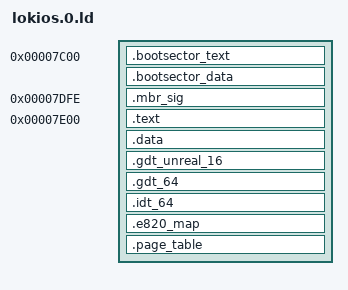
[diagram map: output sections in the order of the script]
SECTIONS
{
    /* PXE loads us into memory at 0x7c00, so link ourselves at that base
     * address. */
    . = 0x7c00;
    .bootsector_text :
    {
        lokios.0/bootsector/entry.o(.text)
        lokios.0/bootsector/*(.text)
    }
    .bootsector_data :
    {
        lokios.0/bootsector/*(.data)
    }
    ASSERT(. <= 0x7DB4, "boot sector crashed into disk ID")

    /* Include a valid MBR signature for booting off disk. */
    . = 0x7dfe;
    .mbr_sig :
    {
        BYTE(0x55)
        BYTE(0xAA)
    }

    /* That's the end of the boot sector.  If we PXE-booted the rest of the
     * code is already in memory.  If we MBR-booted then the bootsector has
     * gone and loaded the rest of the code into memory.  In either case, they
     * will then branch into code at or above 0x7E00. */
    . = 0x7e00;
    .text :
    {
        *(.text)
    }
    .data :
    {
        *(.data)
    } = 0xCC

    /* Provide a global descriptor table to use for the swtich to 16-bit
     * unreal mode. */
    . = ALIGN(64);
    .gdt_unreal_16 :
    {
        _gdt_unreal_16 = .;
        QUAD(0x0000000000000000);
        QUAD(0x00CF92000000FFFF);

        _gdt_unreal_16_desc = .;
        SHORT(_gdt_unreal_16_desc - _gdt_unreal_16 - 1);
        LONG(_gdt_unreal_16);
    }

    /* Provide a global descriptor table to use for the switch to 64-bit
     * mode. */
    . = ALIGN(64);
    .gdt_64 :
    {
        _gdt_64 = .;
        QUAD(0x0000000000000000);
        QUAD(0x00209A0000000000);   /* Code descriptor */
        QUAD(0x0000920000000000);   /* Data descriptor */

        _gdt_64_desc = .;
        SHORT(_gdt_64_desc - _gdt_64 - 1);
        LONG(_gdt_64);
    }

    /* Provide an empty interrupt descriptor table.  TODO: Figure out what to
     * really put here. */
    . = ALIGN(64);
    .idt_64 :
    {
        _idt_64 = .;
        BYTE(0);
        _idt_64_desc = .;
        SHORT(_idt_64_desc - _idt_64 - 1);
        LONG(_idt_64);
    }

    /* Provide at least 4096 bytes to hold the E820 map.  This should be more
     * than enough (I hope).  Before we've loaded the E820 map, this region of
     * memory can also be used for a disk IO bounce buffer. */
    .e820_map :
    {
        _pre_e820_bounce_buffer = .;
        _e820_end = .;
        SHORT(0xFFFF);
        _e820_map = .;
        . += 4096;
        . = ALIGN(4096);
    } = 0xDD
    _e820_last_max_entry = . - 24;

    /* Provide a page table that identity-maps the first 4M of memory via a
     * huge page. */
    .page_table :
    {
        _page_table = .;
        ASSERT(_page_table == ALIGN(4096), "page table misaligned");
        QUAD((_page_table + 0x00001000) | 3);
        . = ALIGN(4096);
        QUAD((_page_table + 0x00002000) | 3);
        . = ALIGN(4096);
        QUAD((_page_table + 0x00003000) | 3);
        QUAD(0x0000000000200083);
        . = ALIGN(4096);
        QUAD(0x0000000000000081);
        QUAD(0x0000000000001081);
        QUAD(0x0000000000002081);
        QUAD(0x0000000000003081);
        QUAD(0x0000000000004081);
        QUAD(0x0000000000005081);
        QUAD(0x0000000000006081);
        QUAD(0x0000000000007081);
        QUAD(0x0000000000008081);
        QUAD(0x0000000000009081);
        QUAD(0x000000000000A081);
        QUAD(0x000000000000B081);
        QUAD(0x000000000000C081);
        QUAD(0x000000000000D081);
        QUAD(0x000000000000E081);
        QUAD(0x000000000000F081);
        QUAD(0x0000000000010081);
        QUAD(0x0000000000011081);
        QUAD(0x0000000000012081);
        QUAD(0x0000000000013081);
        QUAD(0x0000000000014081);
        QUAD(0x0000000000015081);
        QUAD(0x0000000000016081);
        QUAD(0x0000000000017081);
        QUAD(0x0000000000018081);
        QUAD(0x0000000000019081);
        QUAD(0x000000000001A081);
        QUAD(0x000000000001B081);
        QUAD(0x000000000001C081);
        QUAD(0x000000000001D081);
        QUAD(0x000000000001E081);
        QUAD(0x000000000001F081);
        QUAD(0x0000000000020081);
        QUAD(0x0000000000021081);
        QUAD(0x0000000000022081);
        QUAD(0x0000000000023081);
        QUAD(0x0000000000024081);
        QUAD(0x0000000000025081);
        QUAD(0x0000000000026081);
        QUAD(0x0000000000027081);
        QUAD(0x0000000000028081);
        QUAD(0x0000000000029081);
        QUAD(0x000000000002A081);
        QUAD(0x000000000002B081);
        QUAD(0x000000000002C081);
        QUAD(0x000000000002D081);
        QUAD(0x000000000002E081);
        QUAD(0x000000000002F081);
        QUAD(0x0000000000030081);
        QUAD(0x0000000000031081);
        QUAD(0x0000000000032081);
        QUAD(0x0000000000033081);
        QUAD(0x0000000000034081);
        QUAD(0x0000000000035081);
        QUAD(0x0000000000036081);
        QUAD(0x0000000000037081);
        QUAD(0x0000000000038081);
        QUAD(0x0000000000039081);
        QUAD(0x000000000003A081);
        QUAD(0x000000000003B081);
        QUAD(0x000000000003C081);
        QUAD(0x000000000003D081);
        QUAD(0x000000000003E081);
        QUAD(0x000000000003F081);
        QUAD(0x0000000000040081);
        QUAD(0x0000000000041081);
        QUAD(0x0000000000042081);
        QUAD(0x0000000000043081);
        QUAD(0x0000000000044081);
        QUAD(0x0000000000045081);
        QUAD(0x0000000000046081);
        QUAD(0x0000000000047081);
        QUAD(0x0000000000048081);
        QUAD(0x0000000000049081);
        QUAD(0x000000000004A081);
        QUAD(0x000000000004B081);
        QUAD(0x000000000004C081);
        QUAD(0x000000000004D081);
        QUAD(0x000000000004E081);
        QUAD(0x000000000004F081);
        QUAD(0x0000000000050081);
        QUAD(0x0000000000051081);
        QUAD(0x0000000000052081);
        QUAD(0x0000000000053081);
        QUAD(0x0000000000054081);
        QUAD(0x0000000000055081);
        QUAD(0x0000000000056081);
        QUAD(0x0000000000057081);
        QUAD(0x0000000000058081);
        QUAD(0x0000000000059081);
        QUAD(0x000000000005A081);
        QUAD(0x000000000005B081);
        QUAD(0x000000000005C081);
        QUAD(0x000000000005D081);
        QUAD(0x000000000005E081);
        QUAD(0x000000000005F081);
        QUAD(0x0000000000060081);
        QUAD(0x0000000000061081);
        QUAD(0x0000000000062081);
        QUAD(0x0000000000063081);
        QUAD(0x0000000000064081);
        QUAD(0x0000000000065081);
        QUAD(0x0000000000066081);
        QUAD(0x0000000000067081);
        QUAD(0x0000000000068081);
        QUAD(0x0000000000069081);
        QUAD(0x000000000006A081);
        QUAD(0x000000000006B081);
        QUAD(0x000000000006C081);
        QUAD(0x000000000006D081);
        QUAD(0x000000000006E081);
        QUAD(0x000000000006F081);
        QUAD(0x0000000000070081);
        QUAD(0x0000000000071081);
        QUAD(0x0000000000072081);
        QUAD(0x0000000000073081);
        QUAD(0x0000000000074081);
        QUAD(0x0000000000075081);
        QUAD(0x0000000000076081);
        QUAD(0x0000000000077081);
        QUAD(0x0000000000078081);
        QUAD(0x0000000000079081);
        QUAD(0x000000000007A081);
        QUAD(0x000000000007B081);
        QUAD(0x000000000007C081);
        QUAD(0x000000000007D081);
        QUAD(0x000000000007E081);
        QUAD(0x000000000007F081);
        QUAD(0x0000000000080081);
        QUAD(0x0000000000081081);
        QUAD(0x0000000000082081);
        QUAD(0x0000000000083081);
        QUAD(0x0000000000084081);
        QUAD(0x0000000000085081);
        QUAD(0x0000000000086081);
        QUAD(0x0000000000087081);
        QUAD(0x0000000000088081);
        QUAD(0x0000000000089081);
        QUAD(0x000000000008A081);
        QUAD(0x000000000008B081);
        QUAD(0x000000000008C081);
        QUAD(0x000000000008D081);
        QUAD(0x000000000008E081);
        QUAD(0x000000000008F081);
        QUAD(0x0000000000090081);
        QUAD(0x0000000000091081);
        QUAD(0x0000000000092081);
        QUAD(0x0000000000093081);
        QUAD(0x0000000000094081);
        QUAD(0x0000000000095081);
        QUAD(0x0000000000096081);
        QUAD(0x0000000000097081);
        QUAD(0x0000000000098081);
        QUAD(0x0000000000099081);
        QUAD(0x000000000009A081);
        QUAD(0x000000000009B081);
        QUAD(0x000000000009C081);
        QUAD(0x000000000009D081);
        QUAD(0x000000000009E081);
        QUAD(0x000000000009F081);
        QUAD(0x00000000000A0081);
        QUAD(0x00000000000A1081);
        QUAD(0x00000000000A2081);
        QUAD(0x00000000000A3081);
        QUAD(0x00000000000A4081);
        QUAD(0x00000000000A5081);
        QUAD(0x00000000000A6081);
        QUAD(0x00000000000A7081);
        QUAD(0x00000000000A8081);
        QUAD(0x00000000000A9081);
        QUAD(0x00000000000AA081);
        QUAD(0x00000000000AB081);
        QUAD(0x00000000000AC081);
        QUAD(0x00000000000AD081);
        QUAD(0x00000000000AE081);
        QUAD(0x00000000000AF081);
        QUAD(0x00000000000B0081);
        QUAD(0x00000000000B1081);
        QUAD(0x00000000000B2081);
        QUAD(0x00000000000B3081);
        QUAD(0x00000000000B4081);
        QUAD(0x00000000000B5081);
        QUAD(0x00000000000B6081);
        QUAD(0x00000000000B7081);
        QUAD(0x00000000000B8083); /* VRAM */
        QUAD(0x00000000000B9083); /* VRAM */
        QUAD(0x00000000000BA083); /* VRAM */
        QUAD(0x00000000000BB083); /* VRAM */
        QUAD(0x00000000000BC083); /* VRAM */
        QUAD(0x00000000000BD083); /* VRAM */
        QUAD(0x00000000000BE083); /* VRAM */
        QUAD(0x00000000000BF083); /* VRAM */
        QUAD(0x00000000000C0081);
        QUAD(0x00000000000C1081);
        QUAD(0x00000000000C2081);
        QUAD(0x00000000000C3081);
        QUAD(0x00000000000C4081);
        QUAD(0x00000000000C5081);
        QUAD(0x00000000000C6081);
        QUAD(0x00000000000C7081);
        QUAD(0x00000000000C8081);
        QUAD(0x00000000000C9081);
        QUAD(0x00000000000CA081);
        QUAD(0x00000000000CB081);
        QUAD(0x00000000000CC081);
        QUAD(0x00000000000CD081);
        QUAD(0x00000000000CE081);
        QUAD(0x00000000000CF081);
        QUAD(0x00000000000D0081);
        QUAD(0x00000000000D1081);
        QUAD(0x00000000000D2081);
        QUAD(0x00000000000D3081);
        QUAD(0x00000000000D4081);
        QUAD(0x00000000000D5081);
        QUAD(0x00000000000D6081);
        QUAD(0x00000000000D7081);
        QUAD(0x00000000000D8081);
        QUAD(0x00000000000D9081);
        QUAD(0x00000000000DA081);
        QUAD(0x00000000000DB081);
        QUAD(0x00000000000DC081);
        QUAD(0x00000000000DD081);
        QUAD(0x00000000000DE081);
        QUAD(0x00000000000DF081);
        QUAD(0x00000000000E0081);
        QUAD(0x00000000000E1081);
        QUAD(0x00000000000E2081);
        QUAD(0x00000000000E3081);
        QUAD(0x00000000000E4081);
        QUAD(0x00000000000E5081);
        QUAD(0x00000000000E6081);
        QUAD(0x00000000000E7081);
        QUAD(0x00000000000E8081);
        QUAD(0x00000000000E9081);
        QUAD(0x00000000000EA081);
        QUAD(0x00000000000EB081);
        QUAD(0x00000000000EC081);
        QUAD(0x00000000000ED081);
        QUAD(0x00000000000EE081);
        QUAD(0x00000000000EF081);
        QUAD(0x00000000000F0081);
        QUAD(0x00000000000F1081);
        QUAD(0x00000000000F2081);
        QUAD(0x00000000000F3081);
        QUAD(0x00000000000F4081);
        QUAD(0x00000000000F5081);
        QUAD(0x00000000000F6081);
        QUAD(0x00000000000F7081);
        QUAD(0x00000000000F8081);
        QUAD(0x00000000000F9081);
        QUAD(0x00000000000FA081);
        QUAD(0x00000000000FB081);
        QUAD(0x00000000000FC081);
        QUAD(0x00000000000FD081);
        QUAD(0x00000000000FE081);
        QUAD(0x00000000000FF081);
        QUAD(0x0000000000100081);
        QUAD(0x0000000000101081);
        QUAD(0x0000000000102081);
        QUAD(0x0000000000103081);
        QUAD(0x0000000000104081);
        QUAD(0x0000000000105081);
        QUAD(0x0000000000106081);
        QUAD(0x0000000000107081);
        QUAD(0x0000000000108081);
        QUAD(0x0000000000109081);
        QUAD(0x000000000010A081);
        QUAD(0x000000000010B081);
        QUAD(0x000000000010C081);
        QUAD(0x000000000010D081);
        QUAD(0x000000000010E081);
        QUAD(0x000000000010F081);
        QUAD(0x0000000000110081);
        QUAD(0x0000000000111081);
        QUAD(0x0000000000112081);
        QUAD(0x0000000000113081);
        QUAD(0x0000000000114081);
        QUAD(0x0000000000115081);
        QUAD(0x0000000000116081);
        QUAD(0x0000000000117081);
        QUAD(0x0000000000118081);
        QUAD(0x0000000000119081);
        QUAD(0x000000000011A081);
        QUAD(0x000000000011B081);
        QUAD(0x000000000011C081);
        QUAD(0x000000000011D081);
        QUAD(0x000000000011E081);
        QUAD(0x000000000011F081);
        QUAD(0x0000000000120081);
        QUAD(0x0000000000121081);
        QUAD(0x0000000000122081);
        QUAD(0x0000000000123081);
        QUAD(0x0000000000124081);
        QUAD(0x0000000000125081);
        QUAD(0x0000000000126081);
        QUAD(0x0000000000127081);
        QUAD(0x0000000000128081);
        QUAD(0x0000000000129081);
        QUAD(0x000000000012A081);
        QUAD(0x000000000012B081);
        QUAD(0x000000000012C081);
        QUAD(0x000000000012D081);
        QUAD(0x000000000012E081);
        QUAD(0x000000000012F081);
        QUAD(0x0000000000130081);
        QUAD(0x0000000000131081);
        QUAD(0x0000000000132081);
        QUAD(0x0000000000133081);
        QUAD(0x0000000000134081);
        QUAD(0x0000000000135081);
        QUAD(0x0000000000136081);
        QUAD(0x0000000000137081);
        QUAD(0x0000000000138081);
        QUAD(0x0000000000139081);
        QUAD(0x000000000013A081);
        QUAD(0x000000000013B081);
        QUAD(0x000000000013C081);
        QUAD(0x000000000013D081);
        QUAD(0x000000000013E081);
        QUAD(0x000000000013F081);
        QUAD(0x0000000000140081);
        QUAD(0x0000000000141081);
        QUAD(0x0000000000142081);
        QUAD(0x0000000000143081);
        QUAD(0x0000000000144081);
        QUAD(0x0000000000145081);
        QUAD(0x0000000000146081);
        QUAD(0x0000000000147081);
        QUAD(0x0000000000148081);
        QUAD(0x0000000000149081);
        QUAD(0x000000000014A081);
        QUAD(0x000000000014B081);
        QUAD(0x000000000014C081);
        QUAD(0x000000000014D081);
        QUAD(0x000000000014E081);
        QUAD(0x000000000014F081);
        QUAD(0x0000000000150081);
        QUAD(0x0000000000151081);
        QUAD(0x0000000000152081);
        QUAD(0x0000000000153081);
        QUAD(0x0000000000154081);
        QUAD(0x0000000000155081);
        QUAD(0x0000000000156081);
        QUAD(0x0000000000157081);
        QUAD(0x0000000000158081);
        QUAD(0x0000000000159081);
        QUAD(0x000000000015A081);
        QUAD(0x000000000015B081);
        QUAD(0x000000000015C081);
        QUAD(0x000000000015D081);
        QUAD(0x000000000015E081);
        QUAD(0x000000000015F081);
        QUAD(0x0000000000160081);
        QUAD(0x0000000000161081);
        QUAD(0x0000000000162081);
        QUAD(0x0000000000163081);
        QUAD(0x0000000000164081);
        QUAD(0x0000000000165081);
        QUAD(0x0000000000166081);
        QUAD(0x0000000000167081);
        QUAD(0x0000000000168081);
        QUAD(0x0000000000169081);
        QUAD(0x000000000016A081);
        QUAD(0x000000000016B081);
        QUAD(0x000000000016C081);
        QUAD(0x000000000016D081);
        QUAD(0x000000000016E081);
        QUAD(0x000000000016F081);
        QUAD(0x0000000000170081);
        QUAD(0x0000000000171081);
        QUAD(0x0000000000172081);
        QUAD(0x0000000000173081);
        QUAD(0x0000000000174081);
        QUAD(0x0000000000175081);
        QUAD(0x0000000000176081);
        QUAD(0x0000000000177081);
        QUAD(0x0000000000178081);
        QUAD(0x0000000000179081);
        QUAD(0x000000000017A081);
        QUAD(0x000000000017B081);
        QUAD(0x000000000017C081);
        QUAD(0x000000000017D081);
        QUAD(0x000000000017E081);
        QUAD(0x000000000017F081);
        QUAD(0x0000000000180081);
        QUAD(0x0000000000181081);
        QUAD(0x0000000000182081);
        QUAD(0x0000000000183081);
        QUAD(0x0000000000184081);
        QUAD(0x0000000000185081);
        QUAD(0x0000000000186081);
        QUAD(0x0000000000187081);
        QUAD(0x0000000000188081);
        QUAD(0x0000000000189081);
        QUAD(0x000000000018A081);
        QUAD(0x000000000018B081);
        QUAD(0x000000000018C081);
        QUAD(0x000000000018D081);
        QUAD(0x000000000018E081);
        QUAD(0x000000000018F081);
        QUAD(0x0000000000190081);
        QUAD(0x0000000000191081);
        QUAD(0x0000000000192081);
        QUAD(0x0000000000193081);
        QUAD(0x0000000000194081);
        QUAD(0x0000000000195081);
        QUAD(0x0000000000196081);
        QUAD(0x0000000000197081);
        QUAD(0x0000000000198081);
        QUAD(0x0000000000199081);
        QUAD(0x000000000019A081);
        QUAD(0x000000000019B081);
        QUAD(0x000000000019C081);
        QUAD(0x000000000019D081);
        QUAD(0x000000000019E081);
        QUAD(0x000000000019F081);
        QUAD(0x00000000001A0081);
        QUAD(0x00000000001A1081);
        QUAD(0x00000000001A2081);
        QUAD(0x00000000001A3081);
        QUAD(0x00000000001A4081);
        QUAD(0x00000000001A5081);
        QUAD(0x00000000001A6081);
        QUAD(0x00000000001A7081);
        QUAD(0x00000000001A8081);
        QUAD(0x00000000001A9081);
        QUAD(0x00000000001AA081);
        QUAD(0x00000000001AB081);
        QUAD(0x00000000001AC081);
        QUAD(0x00000000001AD081);
        QUAD(0x00000000001AE081);
        QUAD(0x00000000001AF081);
        QUAD(0x00000000001B0081);
        QUAD(0x00000000001B1081);
        QUAD(0x00000000001B2081);
        QUAD(0x00000000001B3081);
        QUAD(0x00000000001B4081);
        QUAD(0x00000000001B5081);
        QUAD(0x00000000001B6081);
        QUAD(0x00000000001B7081);
        QUAD(0x00000000001B8081);
        QUAD(0x00000000001B9081);
        QUAD(0x00000000001BA081);
        QUAD(0x00000000001BB081);
        QUAD(0x00000000001BC081);
        QUAD(0x00000000001BD081);
        QUAD(0x00000000001BE081);
        QUAD(0x00000000001BF081);
        QUAD(0x00000000001C0081);
        QUAD(0x00000000001C1081);
        QUAD(0x00000000001C2081);
        QUAD(0x00000000001C3081);
        QUAD(0x00000000001C4081);
        QUAD(0x00000000001C5081);
        QUAD(0x00000000001C6081);
        QUAD(0x00000000001C7081);
        QUAD(0x00000000001C8081);
        QUAD(0x00000000001C9081);
        QUAD(0x00000000001CA081);
        QUAD(0x00000000001CB081);
        QUAD(0x00000000001CC081);
        QUAD(0x00000000001CD081);
        QUAD(0x00000000001CE081);
        QUAD(0x00000000001CF081);
        QUAD(0x00000000001D0081);
        QUAD(0x00000000001D1081);
        QUAD(0x00000000001D2081);
        QUAD(0x00000000001D3081);
        QUAD(0x00000000001D4081);
        QUAD(0x00000000001D5081);
        QUAD(0x00000000001D6081);
        QUAD(0x00000000001D7081);
        QUAD(0x00000000001D8081);
        QUAD(0x00000000001D9081);
        QUAD(0x00000000001DA081);
        QUAD(0x00000000001DB081);
        QUAD(0x00000000001DC081);
        QUAD(0x00000000001DD081);
        QUAD(0x00000000001DE081);
        QUAD(0x00000000001DF081);
        QUAD(0x00000000001E0081);
        QUAD(0x00000000001E1081);
        QUAD(0x00000000001E2081);
        QUAD(0x00000000001E3081);
        QUAD(0x00000000001E4081);
        QUAD(0x00000000001E5081);
        QUAD(0x00000000001E6081);
        QUAD(0x00000000001E7081);
        QUAD(0x00000000001E8081);
        QUAD(0x00000000001E9081);
        QUAD(0x00000000001EA081);
        QUAD(0x00000000001EB081);
        QUAD(0x00000000001EC081);
        QUAD(0x00000000001ED081);
        QUAD(0x00000000001EE081);
        QUAD(0x00000000001EF081);   /* Guard page */
        QUAD(0x00000000001F0083);   /* Kernel stack */
        QUAD(0x00000000001F1083);   /* Kernel stack */
        QUAD(0x00000000001F2083);   /* Kernel stack */
        QUAD(0x00000000001F3083);   /* Kernel stack */
        QUAD(0x00000000001F4083);   /* Kernel stack */
        QUAD(0x00000000001F5083);   /* Kernel stack */
        QUAD(0x00000000001F6083);   /* Kernel stack */
        QUAD(0x00000000001F7083);   /* Kernel stack */
        QUAD(0x00000000001F8083);   /* Kernel stack */
        QUAD(0x00000000001F9083);   /* Kernel stack */
        QUAD(0x00000000001FA083);   /* Kernel stack */
        QUAD(0x00000000001FB083);   /* Kernel stack */
        QUAD(0x00000000001FC083);   /* Kernel stack */
        QUAD(0x00000000001FD081);   /* Guard page - read only, holds kargs*/
        QUAD(0x00000000001FE083);   /* Kernel TLS */
        QUAD(0x00000000001FF081);   /* Guard page */
        . = ALIGN(4096);
    }

    /* We'll switch to a 3K stack from 0xF000 - 0xFC00. */
    _stack_bottom = 0xF000;
    _stack_top    = 0xFC00;

    /* Make sure we didn't crash into the stack. */
    ASSERT(. <= _stack_bottom, "image crashed into the low stack address")

    /* Compute the number of sectors the MBR loader needs to read. */
    _extra_sectors = (. - 0x7e00) / 512;

    /* This is where we are going to load the kernel. */
    _kernel_base = 0x00200000;
    _kernel_entry = _kernel_base + 0x10;
    _kernel_stack = 0x001FD000;
    _kernel_params = _kernel_stack;
    _kernel_tls_page = 0x001FE000;
    _kernel_tls = _kernel_tls_page + 0x800;
}
